# platform_designer_hps_system_hps_0_hps register map
Vendor: default_vendor.com; File version: 0.0
Registers are 32-bit, read-write, reset 0x0 unless marked. A register's access mark holds for its fields unless they carry their own. Offsets are from the block's base; [hi:lo] are bit positions; {n}, {i} and the like mark numbered series.

## spim0 — Registers in the SPI Master module
Base 0xFFF00000
Same registers: spim1 0xFFF01000
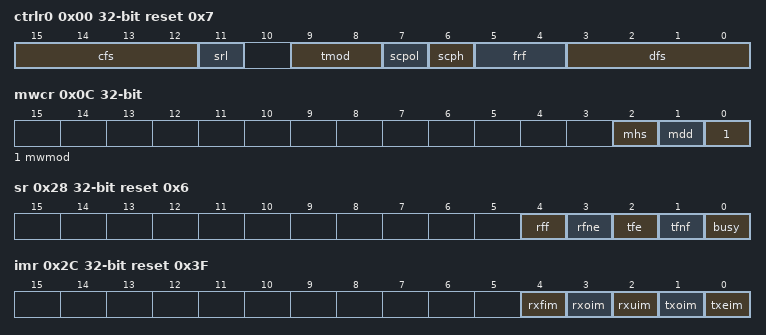
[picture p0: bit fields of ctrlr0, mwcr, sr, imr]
0x00 ctrlr0 reset 0x7 — This register controls the serial data transfer. It is impossible to write to this register when the SPI Master is enabled. The SPI Master is enabled and disabled by writing to the SPIENR register.
  [15:12] cfs — Selects the length of the control word for the Microwire frame format. The length (in bits) is the value of this field plus 1.
  [11] srl — Used for testing purposes only. When internally active, connects the transmit shift register output to the receive shift register input.
    0=normmode; 1=testmode
  [9:8] tmod — Selects the mode of transfer for serial communication. This field does not affect the transfer duplicity. Only indicates whether the receive or transmit data are valid. In transmit-only mode, data received from the external device is not valid and is not stored in the receive FIFO memory. It is overwritten on the next transfer. In receive-only mode, transmitted data are not valid. After the first write to the transmit FIFO, the same word is retransmitted for the duration of the transfer. In transmit-and-receive mode, both transmit and receive data are valid. The transfer continues until the transmit FIFO is empty. Data received from the external device are stored into the receive FIFO memory, where it can be accessed by the host processor.
    0=txrx; 1=txonly; 2=rxonly; 3=eerd
  [7] scpol — Valid when the frame format (FRF) is set to Motorola SPI. Used to select the polarity of the inactive serial clock, which is held inactive when the SPI Master is not actively transferring data on the serial bus.
    0=inactivelow; 1=inactivehigh
  [6] scph — Valid when the frame format (FRF) is set to Motorola SPI. The serial clock phase selects the relationship of the serial clock with the slave select signal. When SCPH = 0, data are captured on the first edge of the serial clock. When SCPH = 1, the serial clock starts toggling one cycle after the slave select line is activated, and data are captured on the second edge of the serial clock.
    0=midbit; 1=startbit
  [5:4] frf — Selects which serial protocol transfers the data.
    0=motspi; 1=tissp; 2=natmw
  [3:0] dfs — Selects the data frame length. When the data frame size is programmed to be less than 16 bits, the receive data are automatically right-justified by the receive logic, with the upper bits of the receive FIFO zero-padded. You must right-justify transmit data before writing into the transmit FIFO. The transmit logic ignores the upper unused bits when transmitting the data.
    {v}=width{v+1}bit (v=3..9)
0x04 ctrlr1 — Control register 1 controls the end of serial transfers when in receive-only mode. It is impossible to write to this register when the SPI Master is enabled.The SPI Master is enabled and disabled by writing to the SPIENR register.
  [15:0] ndf — When TMOD = 10 or TMOD =11, this register field sets the number of data frames to be continuously received by the SPI Master. The SPI Master continues to receive serial data until the number of data frames received is equal to this register value plus 1, which enables you to receive up to 64 KB of data in a continuous transfer.
0x08 spienr — Enables and Disables all SPI operations.
  [0] spi_en — Enables and disables all SPI Master operations. When disabled, all serial transfers are halted immediately. Transmit and receive FIFO buffers are cleared when the device is disabled. It is impossible to program some of the SPI Master control registers when enabled.
    0=disabled; 1=enabled
0x0C mwcr — This register controls the direction of the data word for the half-duplex Microwire serial protocol. It is impossible to write to this register when the SPI Master is enabled. The SPI Master is enabled and disabled by writing to the SPIENR register.
  [2] mhs — Used to enable and disable the busy/ready handshaking interface for the Microwire protocol. When enabled, the SPI Master checks for a ready status from the target slave, after the transfer of the last data/control bit, before clearing the BUSY status in the SR register.
    0=disabled; 1=enabled
  [1] mdd — Defines the direction of the data word when the Microwire serial protocol is used.
    0=rxmode; 1=txmode
  [0] mwmod — Defines whether the Microwire transfer is sequential or non-sequential. When sequential mode is used, only one control word is needed to transmit or receive a block of data words. When non-sequential mode is used, there must be a control word for each data word that is transmitted or received.
    0=nonseq; 1=seq
0x10 ser — The register enables the individual slave select output lines from the SPI Master. Up to 4 slave-select output pins are available on the SPI Master. You cannot write to this register when SPI Master is busy and when SPI_EN = 1.
  [3:0] ser — Each bit in this register corresponds to a slave select line (spim_ss_x_n] from the SPI Master. When a bit in this register is set (1), the corresponding slave select line from the master is activated when a serial transfer begins. It should be noted that setting or clearing bits in this register have no effect on the corresponding slave select outputs until a transfer is started. Before beginning a transfer, you should enable the bit in this register that corresponds to the slave device with which the master wants to communicate. When not operating in broadcast mode, only one bit in this field should be set.
    0=notselected; 1=selected
0x14 baudr — This register derives the frequency of the serial clock that regulates the data transfer. The 16-bit field in this register defines the spi_m_clk divider value. It is impossible to write to this register when the SPI Master is enabled. The SPI Master is enabled and disabled by writing to the SPIENR register.
  [15:0] sckdv — The LSB for this field is always set to 0 and is unaffected by a write operation, which ensures an even value is held in this register. If the value is 0, the serial output clock (spim_sclk_out) is disabled. The frequency of the spim_sclk_out is derived from the following equation: Fspim_sclk_out = Fspi_m_clk/SCKDV where SCKDV is any even value between 2 and 65534. For example: for Fspi_m_clk = 3.6864MHz and SCKDV =2 Fspim_sclk_out = 3.6864/2 = 1.8432MHz
0x18 txftlr — This register controls the threshold value for the transmit FIFO memory. It is impossible to write to this register when the SPI Master is enabled. The SPI Master is enabled and disabled by writing to the SPIENR register.
  [7:0] tft — Controls the level of entries (or below) at which the transmit FIFO controller triggers an interrupt. When the number of transmit FIFO entries is less than or equal to this value, the transmit FIFO empty interrupt is triggered.
0x1C rxftlr — This register controls the threshold value for the receive FIFO memory. It is impossible to write to this register when the SPI Master is enabled. The SPI Master is enabled and disabled by writing to the SPIENR register.
  [7:0] rft — Controls the level of entries (or above) at which the receive FIFO controller triggers an interrupt. When the number of receive FIFO entries is greater than or equal to this value + 1, the receive FIFO full interrupt is triggered.
0x20 txflr ro — This register contains the number of valid data entries in the transmit FIFO memory. Ranges from 0 to 256.
  [8:0] txtfl — Contains the number of valid data entries in the transmit FIFO.
0x24 rxflr ro — This register contains the number of valid data entries in the receive FIFO memory. This register can be read at any time. Ranges from 0 to 256.
  [8:0] rxtfl — Contains the number of valid data entries in the receive FIFO.
0x28 sr ro reset 0x6 — This register is used to indicate the current transfer status, FIFO status, and any transmission/reception errors that may have occurred. The status register may be read at any time. None of the bits in this register request an interrupt.
  [4] rff — Reports receive FIFO condition.
    0=notfull; 1=full
  [3] rfne — Reports receive FIFO condition.
    0=empty; 1=notempty
  [2] tfe — Reports transmit FIFO condition.
    1=empty; 0=notempty
  [1] tfnf — Reports transmit FIFO condition.
    0=full; 1=notfull
  [0] busy — Reports the staus of a serial transfer
    0=inactive; 1=active
0x2C imr reset 0x3F — This register masks or enables all interrupts generated by the SPI Master.
  [all] fields
    0=masked; 1=enabled
  [4] rxfim — Full Mask
  [3] rxoim — Overflow Mask.
  [2] rxuim — Underflow Mask
  [1] txoim — Overflow Mask
  [0] txeim — Empty mask.
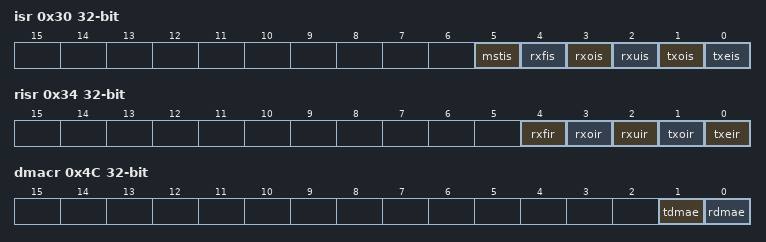
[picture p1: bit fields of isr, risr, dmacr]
0x30 isr ro — This register reports the status of the SPI Master interrupts after they have been masked.
  [all] fields
    0=inactive; 1=active
  [5] mstis — Multi-master contention status.
  [4] rxfis — Full Status.
  [3] rxois — Overflow Status.
  [2] rxuis — Underflow Status.
  [1] txois — Overflow Status.
  [0] txeis — Empty status.
0x34 risr ro — This register reports the status of the SPI Master interrupts prior to masking.
  [4] rxfir — The interrupt is active or inactive prior to masking.
    0=inactive; 1=active
  [3] rxoir — The interrupt is active or inactive prior to masking.
    0=inactove; 1=active
  [2] rxuir — The interrupt is active or inactive prior to masking.
    0=inactive; 1=active
  [1] txoir — The interrupt is active or inactive prior to masking.
    0=inactive; 1=active
  [0] txeir — The interrupt is active or inactive prior to masking.
    0=inactive; 1=active
0x38 txoicr ro — Transmit FIFO Overflow Interrupt Clear Register
  [0] txoicr — This register reflects the status of the interrupt. A read from this register clears the spi_txo_intr interrupt; writing has no effect.
0x3C rxoicr ro — Receive FIFO Overflow Interrupt Clear Register
  [0] rxoicr — This register reflects the status of the interrupt. A read from this register clears the spi_rxo_intr interrupt; writing has no effect.
0x40 rxuicr ro — Receive FIFO Underflow Interrupt Clear Register
  [0] rxuicr — This register reflects the status of the interrupt. A read from this register clears the spi_rxu_intr interrupt; writing has no effect.
0x48 icr ro — Clear Interrupt
  [0] icr — This register is set if any of the interrupts are active. A read clears the spi_txo_intr, spi_rxu_intr, spi_rxo_intr, and the spi_mst_intr interrupts. Writing to this register has no effect.
0x4C dmacr — This register is used to enable the DMA Controller interface operation.
  [1] tdmae — This bit enables/disables the transmit FIFO DMA channel.
    0=disabled; 1=enabled
  [0] rdmae — This bit enables/disables the receive FIFO DMA channel.
    0=disabled; 1=enabled
0x50 dmatdlr — Controls the FIFO Level for a DMA transmit request
  [7:0] dmatdl — This bit field controls the level at which a DMA request is made by the transmit logic. It is equal to the watermark level; that is, the dma_tx_req signal is generated when the number of valid data entries in the transmit FIFO is equal to or below this field value, and TDMAE = 1.
0x54 dmardlr — Controls the FIFO Level for a DMA receeive request
  [7:0] dmardl — This bit field controls the level at which a DMA request is made by the receive logic. The watermark level = DMARDL+1; that is, dma_rx_req is generated when the number of valid data entries in the receive FIFO is equal to or above this field value + 1, and RDMAE=1.
0x58 idr ro reset 0x5510000 — This register contains the peripherals identification code, which is 0x05510000.
  [31:0] idr — This register contains the peripherals identification code
0x5C spi_version_id reset 0x3332302A — Version ID Register value
  [31:0] spi_version_id — Contains the hex representation of the Synopsys component version. Consists of ASCII value for each number in the version.
0x60 dr — This register is a 16-bit read/write buffer for the transmit/receive FIFOs. When the register is read, data in the receive FIFO buffer is accessed. When it is written to, data are moved into the transmit FIFO buffer; a write can occur only when SPI_EN = 1. FIFOs are reset when SPI_EN = 0. The data register occupies 36 32-bit locations in the address map (0x60 to 0xec). These are all aliases for the same data register. This is done to support burst accesses.
  [15:0] dr — When writing to this register, you must right-justify the data. Read data are automatically right-justified. Read = Receive FIFO buffer Write = Transmit FIFO buffer
0xFC rx_sample_dly — This register controls the number of spi_m_clk cycles that are delayed (from the default sample time) before the actual sample of the rxd input occurs. It is impossible to write to this register when the SPI Master is enabled. The SPI Master is enabled and disabled by writing to the SPIENR register.
  [6:0] rsd — This register is used to delay the sample of the rxd input port. Each value represents a single spi_m_clk delay on the sample of rxd. Note; If this register is programmed with a value that exceeds 64, a 0 delay will be applied to the receive sample. The maximum delay is 64 spi_m_clk cycles.
